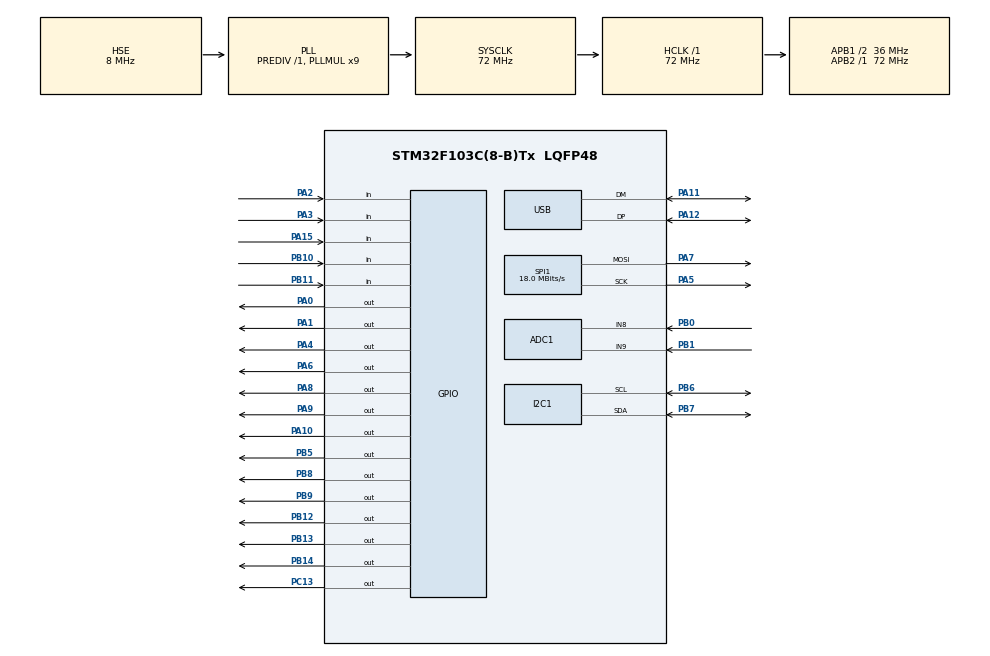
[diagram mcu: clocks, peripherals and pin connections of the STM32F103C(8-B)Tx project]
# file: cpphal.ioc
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ADC1.Channel-23\#ChannelRegularConversion=ADC_CHANNEL_8
ADC1.NbrOfConversionFlag=1
ADC1.Rank-23\#ChannelRegularConversion=1
ADC1.SamplingTime-23\#ChannelRegularConversion=ADC_SAMPLETIME_1CYCLE_5
ADC1.master=1
Mcu.Family=STM32F1
Mcu.Name=STM32F103C(8-B)Tx
Mcu.Package=LQFP48
NVIC.PriorityGroup=NVIC_PRIORITYGROUP_4
NVIC.TIM3_IRQn=true\:0\:0\:false\:false\:true\:true
NVIC.USB_LP_CAN1_RX0_IRQn=true\:0\:0\:false\:false\:true\:false
PA0-WKUP.Signal=GPIO_Output
PA1.Signal=GPIO_Output
PA10.Signal=GPIO_Output
PA11.Mode=Device
PA11.Signal=USB_DM
PA12.Mode=Device
PA12.Signal=USB_DP
PA13.Mode=Serial_Wire
PA13.Signal=SYS_JTMS-SWDIO
PA14.Mode=Serial_Wire
PA14.Signal=SYS_JTCK-SWCLK
PA15.Signal=GPIO_Input
PA2.Signal=GPIO_Input
PA3.Signal=GPIO_Input
PA4.Signal=GPIO_Output
PA5.Mode=TX_Only_Simplex_Unidirect_Master
PA5.Signal=SPI1_SCK
PA6.Signal=GPIO_Output
PA7.Mode=TX_Only_Simplex_Unidirect_Master
PA7.Signal=SPI1_MOSI
PA8.Signal=GPIO_Output
PA9.Signal=GPIO_Output
PB0.Signal=ADCx_IN8
PB1.Signal=ADCx_IN9
PB10.Signal=GPIO_Input
PB11.Signal=GPIO_Input
PB12.Signal=GPIO_Output
PB13.Signal=GPIO_Output
PB14.Signal=GPIO_Output
PB5.Signal=GPIO_Output
PB6.Mode=I2C
PB6.Signal=I2C1_SCL
PB7.Mode=I2C
PB7.Signal=I2C1_SDA
PB8.Signal=GPIO_Output
PB9.Signal=GPIO_Output
PC13-TAMPER-RTC.Signal=GPIO_Output
PD0-OSC_IN.Mode=HSE-External-Oscillator
PD0-OSC_IN.Signal=RCC_OSC_IN
PD1-OSC_OUT.Mode=HSE-External-Oscillator
PD1-OSC_OUT.Signal=RCC_OSC_OUT
ProjectManager.HeapSize=0x200
ProjectManager.StackSize=0x400
ProjectManager.TargetToolchain=Makefile
RCC.ADCPresc=RCC_ADCPCLK2_DIV6
RCC.AHBFreq_Value=72000000
RCC.APB1CLKDivider=RCC_HCLK_DIV2
RCC.APB1Freq_Value=36000000
RCC.APB1TimFreq_Value=72000000
RCC.APB2Freq_Value=72000000
RCC.APB2TimFreq_Value=72000000
RCC.HCLKFreq_Value=72000000
RCC.PLLMUL=RCC_PLL_MUL9
RCC.PLLSourceVirtual=RCC_PLLSOURCE_HSE
RCC.SYSCLKFreq_VALUE=72000000
RCC.SYSCLKSource=RCC_SYSCLKSOURCE_PLLCLK
RCC.USBFreq_Value=48000000
RCC.USBPrescaler=RCC_USBCLKSOURCE_PLL_DIV1_5
SH.ADCx_IN8.0=ADC1_IN8,IN8
SH.ADCx_IN9.0=ADC1_IN9,IN9
SPI1.BaudRatePrescaler=SPI_BAUDRATEPRESCALER_4
SPI1.CalculateBaudRate=18.0 MBits/s
SPI1.Direction=SPI_DIRECTION_2LINES
SPI1.Mode=SPI_MODE_MASTER
SPI1.VirtualType=VM_MASTER
TIM3.Period=500
TIM3.Prescaler=15999
USB_DEVICE.CLASS_NAME_FS=CDC
USB_DEVICE.VirtualMode=Cdc
USB_DEVICE.VirtualModeFS=Cdc_FS
VP_TIM3_VS_ClockSourceINT.Mode=Internal
VP_USB_DEVICE_VS_USB_DEVICE_CDC_FS.Mode=CDC_FS
board=custom

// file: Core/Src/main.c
/* USER CODE BEGIN Header */
/**
  ******************************************************************************
  * @file           : main.c
  * @brief          : Main program body
  ******************************************************************************
  * This notice applies to any and all portions of this file
  * that are not between comment pairs USER CODE BEGIN and
  * USER CODE END. Other portions of this file, whether
  * inserted by the user or by software development tools
  * are owned by their respective copyright owners.
  *
  * Copyright (c) 2019 STMicroelectronics International N.V.
  * All rights reserved.
  *
  * Redistribution and use in source and binary forms, with or without
  * modification, are permitted, provided that the following conditions are met:
  *
  * 1. Redistribution of source code must retain the above copyright notice,
  *    this list of conditions and the following disclaimer.
  * 2. Redistributions in binary form must reproduce the above copyright notice,
  *    this list of conditions and the following disclaimer in the documentation
  *    and/or other materials provided with the distribution.
  * 3. Neither the name of STMicroelectronics nor the names of other
  *    contributors to this software may be used to endorse or promote products
  *    derived from this software without specific written permission.
  * 4. This software, including modifications and/or derivative works of this
  *    software, must execute solely and exclusively on microcontroller or
  *    microprocessor devices manufactured by or for STMicroelectronics.
  * 5. Redistribution and use of this software other than as permitted under
  *    this license is void and will automatically terminate your rights under
  *    this license.
  *
  * THIS SOFTWARE IS PROVIDED BY STMICROELECTRONICS AND CONTRIBUTORS "AS IS"
  * AND ANY EXPRESS, IMPLIED OR STATUTORY WARRANTIES, INCLUDING, BUT NOT
  * LIMITED TO, THE IMPLIED WARRANTIES OF MERCHANTABILITY, FITNESS FOR A
  * PARTICULAR PURPOSE AND NON-INFRINGEMENT OF THIRD PARTY INTELLECTUAL PROPERTY
  * RIGHTS ARE DISCLAIMED TO THE FULLEST EXTENT PERMITTED BY LAW. IN NO EVENT
  * SHALL STMICROELECTRONICS OR CONTRIBUTORS BE LIABLE FOR ANY DIRECT, INDIRECT,
  * INCIDENTAL, SPECIAL, EXEMPLARY, OR CONSEQUENTIAL DAMAGES (INCLUDING, BUT NOT
  * LIMITED TO, PROCUREMENT OF SUBSTITUTE GOODS OR SERVICES; LOSS OF USE, DATA,
  * OR PROFITS; OR BUSINESS INTERRUPTION) HOWEVER CAUSED AND ON ANY THEORY OF
  * LIABILITY, WHETHER IN CONTRACT, STRICT LIABILITY, OR TORT (INCLUDING
  * NEGLIGENCE OR OTHERWISE) ARISING IN ANY WAY OUT OF THE USE OF THIS SOFTWARE,
  * EVEN IF ADVISED OF THE POSSIBILITY OF SUCH DAMAGE.
  *
  ******************************************************************************
  */
/* USER CODE END Header */

#include "main.h"
#include "usb_device.h"

ADC_HandleTypeDef hadc1;

I2C_HandleTypeDef hi2c1;

SPI_HandleTypeDef hspi1;

TIM_HandleTypeDef htim3;

void SystemClock_Config(void);
static void MX_GPIO_Init(void);
static void MX_ADC1_Init(void);
static void MX_SPI1_Init(void);
static void MX_TIM3_Init(void);
static void MX_I2C1_Init(void);

int mainc(void)
{

  /* MCU Configuration--------------------------------------------------------*/

  /* Reset of all peripherals, Initializes the Flash interface and the Systick. */
  HAL_Init();

  /* Configure the system clock */
  SystemClock_Config();

  /* Initialize all configured peripherals */
  MX_GPIO_Init();
  MX_ADC1_Init();
  MX_SPI1_Init();
  MX_TIM3_Init();
  MX_I2C1_Init();
  MX_USB_DEVICE_Init();

  /* Infinite loop */
  while (1)
  {

    /* USER CODE BEGIN 3 */
    break;
  }
  /* USER CODE END 3 */
}

void SystemClock_Config(void)
{
  RCC_OscInitTypeDef RCC_OscInitStruct = {0};
  RCC_ClkInitTypeDef RCC_ClkInitStruct = {0};
  RCC_PeriphCLKInitTypeDef PeriphClkInit = {0};

  /**Initializes the CPU, AHB and APB busses clocks
  */
  RCC_OscInitStruct.OscillatorType = RCC_OSCILLATORTYPE_HSE;
  RCC_OscInitStruct.HSEState = RCC_HSE_ON;
  RCC_OscInitStruct.HSEPredivValue = RCC_HSE_PREDIV_DIV1;
  RCC_OscInitStruct.HSIState = RCC_HSI_ON;
  RCC_OscInitStruct.PLL.PLLState = RCC_PLL_ON;
  RCC_OscInitStruct.PLL.PLLSource = RCC_PLLSOURCE_HSE;
  RCC_OscInitStruct.PLL.PLLMUL = RCC_PLL_MUL9;
  if (HAL_RCC_OscConfig(&RCC_OscInitStruct) != HAL_OK)
  {
    Error_Handler();
  }
  /**Initializes the CPU, AHB and APB busses clocks
  */
  RCC_ClkInitStruct.ClockType = RCC_CLOCKTYPE_HCLK|RCC_CLOCKTYPE_SYSCLK
                              |RCC_CLOCKTYPE_PCLK1|RCC_CLOCKTYPE_PCLK2;
  RCC_ClkInitStruct.SYSCLKSource = RCC_SYSCLKSOURCE_PLLCLK;
  RCC_ClkInitStruct.AHBCLKDivider = RCC_SYSCLK_DIV1;
  RCC_ClkInitStruct.APB1CLKDivider = RCC_HCLK_DIV2;
  RCC_ClkInitStruct.APB2CLKDivider = RCC_HCLK_DIV1;

  if (HAL_RCC_ClockConfig(&RCC_ClkInitStruct, FLASH_LATENCY_2) != HAL_OK)
  {
    Error_Handler();
  }
  PeriphClkInit.PeriphClockSelection = RCC_PERIPHCLK_ADC|RCC_PERIPHCLK_USB;
  PeriphClkInit.AdcClockSelection = RCC_ADCPCLK2_DIV6;
  PeriphClkInit.UsbClockSelection = RCC_USBCLKSOURCE_PLL_DIV1_5;
  if (HAL_RCCEx_PeriphCLKConfig(&PeriphClkInit) != HAL_OK)
  {
    Error_Handler();
  }
}

static void MX_ADC1_Init(void)
{

  ADC_ChannelConfTypeDef sConfig = {0};

  /**Common config
  */
  hadc1.Instance = ADC1;
  hadc1.Init.ScanConvMode = ADC_SCAN_DISABLE;
  hadc1.Init.ContinuousConvMode = DISABLE;
  hadc1.Init.DiscontinuousConvMode = DISABLE;
  hadc1.Init.ExternalTrigConv = ADC_SOFTWARE_START;
  hadc1.Init.DataAlign = ADC_DATAALIGN_RIGHT;
  hadc1.Init.NbrOfConversion = 1;
  if (HAL_ADC_Init(&hadc1) != HAL_OK)
  {
    Error_Handler();
  }
  /**Configure Regular Channel
  */
  sConfig.Channel = ADC_CHANNEL_8;
  sConfig.Rank = ADC_REGULAR_RANK_1;
  sConfig.SamplingTime = ADC_SAMPLETIME_1CYCLE_5;
  if (HAL_ADC_ConfigChannel(&hadc1, &sConfig) != HAL_OK)
  {
    Error_Handler();
  }

}

static void MX_I2C1_Init(void)
{

  hi2c1.Instance = I2C1;
  hi2c1.Init.ClockSpeed = 100000;
  hi2c1.Init.DutyCycle = I2C_DUTYCYCLE_2;
  hi2c1.Init.OwnAddress1 = 0;
  hi2c1.Init.AddressingMode = I2C_ADDRESSINGMODE_7BIT;
  hi2c1.Init.DualAddressMode = I2C_DUALADDRESS_DISABLE;
  hi2c1.Init.OwnAddress2 = 0;
  hi2c1.Init.GeneralCallMode = I2C_GENERALCALL_DISABLE;
  hi2c1.Init.NoStretchMode = I2C_NOSTRETCH_DISABLE;
  if (HAL_I2C_Init(&hi2c1) != HAL_OK)
  {
    Error_Handler();
  }

}

static void MX_SPI1_Init(void)
{

  /* SPI1 parameter configuration*/
  hspi1.Instance = SPI1;
  hspi1.Init.Mode = SPI_MODE_MASTER;
  hspi1.Init.Direction = SPI_DIRECTION_2LINES;
  hspi1.Init.DataSize = SPI_DATASIZE_8BIT;
  hspi1.Init.CLKPolarity = SPI_POLARITY_LOW;
  hspi1.Init.CLKPhase = SPI_PHASE_1EDGE;
  hspi1.Init.NSS = SPI_NSS_SOFT;
  hspi1.Init.BaudRatePrescaler = SPI_BAUDRATEPRESCALER_4;
  hspi1.Init.FirstBit = SPI_FIRSTBIT_MSB;
  hspi1.Init.TIMode = SPI_TIMODE_DISABLE;
  hspi1.Init.CRCCalculation = SPI_CRCCALCULATION_DISABLE;
  hspi1.Init.CRCPolynomial = 10;
  if (HAL_SPI_Init(&hspi1) != HAL_OK)
  {
    Error_Handler();
  }

}

static void MX_TIM3_Init(void)
{

  TIM_ClockConfigTypeDef sClockSourceConfig = {0};
  TIM_MasterConfigTypeDef sMasterConfig = {0};

  htim3.Instance = TIM3;
  htim3.Init.Prescaler = 15999;
  htim3.Init.CounterMode = TIM_COUNTERMODE_UP;
  htim3.Init.Period = 500;
  htim3.Init.ClockDivision = TIM_CLOCKDIVISION_DIV1;
  htim3.Init.AutoReloadPreload = TIM_AUTORELOAD_PRELOAD_DISABLE;
  if (HAL_TIM_Base_Init(&htim3) != HAL_OK)
  {
    Error_Handler();
  }
  sClockSourceConfig.ClockSource = TIM_CLOCKSOURCE_INTERNAL;
  if (HAL_TIM_ConfigClockSource(&htim3, &sClockSourceConfig) != HAL_OK)
  {
    Error_Handler();
  }
  sMasterConfig.MasterOutputTrigger = TIM_TRGO_RESET;
  sMasterConfig.MasterSlaveMode = TIM_MASTERSLAVEMODE_DISABLE;
  if (HAL_TIMEx_MasterConfigSynchronization(&htim3, &sMasterConfig) != HAL_OK)
  {
    Error_Handler();
  }

}

static void MX_GPIO_Init(void)
{
  GPIO_InitTypeDef GPIO_InitStruct = {0};

  /* GPIO Ports Clock Enable */
  __HAL_RCC_GPIOC_CLK_ENABLE();
  __HAL_RCC_GPIOD_CLK_ENABLE();
  __HAL_RCC_GPIOA_CLK_ENABLE();
  __HAL_RCC_GPIOB_CLK_ENABLE();

  /*Configure GPIO pin Output Level */
  HAL_GPIO_WritePin(GPIOC, GPIO_PIN_13, GPIO_PIN_RESET);

  /*Configure GPIO pin Output Level */
  HAL_GPIO_WritePin(GPIOA, GPIO_PIN_0|GPIO_PIN_1|GPIO_PIN_4|GPIO_PIN_6
                          |GPIO_PIN_8|GPIO_PIN_9|GPIO_PIN_10, GPIO_PIN_RESET);

  /*Configure GPIO pin Output Level */
  HAL_GPIO_WritePin(GPIOB, GPIO_PIN_12|GPIO_PIN_13|GPIO_PIN_14|GPIO_PIN_5
                          |GPIO_PIN_8|GPIO_PIN_9, GPIO_PIN_RESET);

  /*Configure GPIO pin : PC13 */
  GPIO_InitStruct.Pin = GPIO_PIN_13;
  GPIO_InitStruct.Mode = GPIO_MODE_OUTPUT_PP;
  GPIO_InitStruct.Pull = GPIO_NOPULL;
  GPIO_InitStruct.Speed = GPIO_SPEED_FREQ_LOW;
  HAL_GPIO_Init(GPIOC, &GPIO_InitStruct);

  /*Configure GPIO pins : PA0 PA1 PA4 PA6
                           PA8 PA9 PA10 */
  GPIO_InitStruct.Pin = GPIO_PIN_0|GPIO_PIN_1|GPIO_PIN_4|GPIO_PIN_6
                          |GPIO_PIN_8|GPIO_PIN_9|GPIO_PIN_10;
  GPIO_InitStruct.Mode = GPIO_MODE_OUTPUT_PP;
  GPIO_InitStruct.Pull = GPIO_NOPULL;
  GPIO_InitStruct.Speed = GPIO_SPEED_FREQ_LOW;
  HAL_GPIO_Init(GPIOA, &GPIO_InitStruct);

  /*Configure GPIO pins : PA2 PA3 PA15 */
  GPIO_InitStruct.Pin = GPIO_PIN_2|GPIO_PIN_3|GPIO_PIN_15;
  GPIO_InitStruct.Mode = GPIO_MODE_INPUT;
  GPIO_InitStruct.Pull = GPIO_NOPULL;
  HAL_GPIO_Init(GPIOA, &GPIO_InitStruct);

  /*Configure GPIO pins : PB10 PB11 */
  GPIO_InitStruct.Pin = GPIO_PIN_10|GPIO_PIN_11;
  GPIO_InitStruct.Mode = GPIO_MODE_INPUT;
  GPIO_InitStruct.Pull = GPIO_NOPULL;
  HAL_GPIO_Init(GPIOB, &GPIO_InitStruct);

  /*Configure GPIO pins : PB12 PB13 PB14 PB5
                           PB8 PB9 */
  GPIO_InitStruct.Pin = GPIO_PIN_12|GPIO_PIN_13|GPIO_PIN_14|GPIO_PIN_5
                          |GPIO_PIN_8|GPIO_PIN_9;
  GPIO_InitStruct.Mode = GPIO_MODE_OUTPUT_PP;
  GPIO_InitStruct.Pull = GPIO_NOPULL;
  GPIO_InitStruct.Speed = GPIO_SPEED_FREQ_LOW;
  HAL_GPIO_Init(GPIOB, &GPIO_InitStruct);

}

void Error_Handler(void)
{
}

/************************ (C) COPYRIGHT STMicroelectronics *****END OF FILE****/
